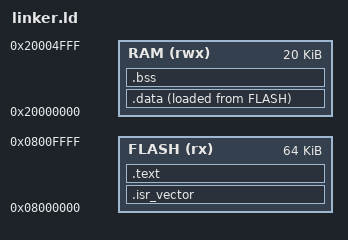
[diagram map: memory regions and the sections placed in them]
ENTRY(Reset_Handler)

_estack = 0x20005000;

MEMORY
{
    FLASH (rx)  : ORIGIN = 0x08000000, LENGTH = 64K
    RAM   (rwx) : ORIGIN = 0x20000000, LENGTH = 20K
}

SECTIONS
{
    .isr_vector :
    {
        KEEP(*(.isr_vector))
    } > FLASH

    .text :
    {
        *(.text)
        *(.text*)
        *(.rodata)
        *(.rodata*)
    } > FLASH

    .data :
    {
        _sdata = .;
        *(.data)
        *(.data*)
        _edata = .;
    } > RAM AT > FLASH

    .bss :
    {
        _sbss = .;
        *(.bss)
        *(.bss*)
        *(COMMON)
        _ebss = .;
    } > RAM
}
